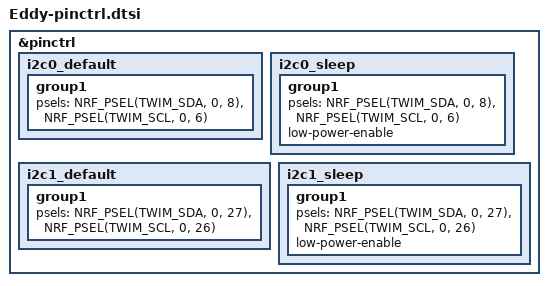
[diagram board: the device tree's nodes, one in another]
&pinctrl {
//     i2s0_default: i2s0_default {
//         group1 {
//             psels = <NRF_PSEL(MCK, 0, 4)>;
// 	    };
//     };	

    i2c0_default: i2c0_default {
        group1 {
            psels = <NRF_PSEL(TWIM_SDA, 0, 8)>,
                <NRF_PSEL(TWIM_SCL, 0, 6)>;
        };
    };

    i2c0_sleep: i2c0_sleep {
        group1 {
            psels = <NRF_PSEL(TWIM_SDA, 0, 8)>,
                <NRF_PSEL(TWIM_SCL, 0, 6)>;
            low-power-enable;
        };
    };

    i2c1_default: i2c1_default {
		group1 {
			psels = <NRF_PSEL(TWIM_SDA, 0, 27)>,
				<NRF_PSEL(TWIM_SCL, 0, 26)>;
		};
	};

	i2c1_sleep: i2c1_sleep {
		group1 {
			psels = <NRF_PSEL(TWIM_SDA, 0, 27)>,
				<NRF_PSEL(TWIM_SCL, 0, 26)>;
			low-power-enable;
		};
	};
};
